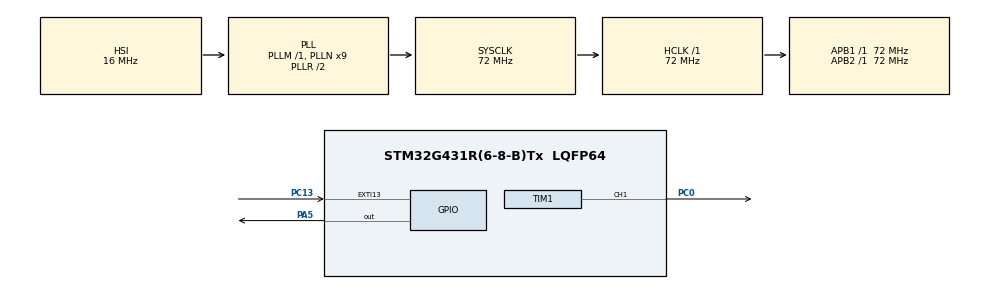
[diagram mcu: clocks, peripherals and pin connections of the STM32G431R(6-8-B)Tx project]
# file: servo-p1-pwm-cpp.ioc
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Mcu.Family=STM32G4
Mcu.Name=STM32G431R(6-8-B)Tx
Mcu.Package=LQFP64
NUCLEO-G431RB.BUTTON=1
NUCLEO-G431RB.LD1=true
NUCLEO-G431RB.VCP=true
NVIC.EXTI15_10_IRQn=true\:0\:0\:false\:false\:true\:false\:true\:true
NVIC.PriorityGroup=NVIC_PRIORITYGROUP_4
PA13.GPIO_Label=T_SWDIO
PA13.Signal=SYS_JTMS-SWDIO
PA14.GPIO_Label=T_SWCLK
PA14.Signal=SYS_JTCK-SWCLK
PA2.Signal=LPUART1_TX
PA3.Signal=LPUART1_RX
PA5.Signal=GPIO_Output
PB3.GPIO_Label=T_SWO
PB3.Signal=SYS_JTDO-SWO
PC0.Signal=S_TIM1_CH1
PC13.Signal=GPXTI13
PC14-OSC32_IN.GPIO_Label=RCC_OSC32_OUT
PC14-OSC32_IN.Signal=RCC_OSC32_IN
PC15-OSC32_OUT.GPIO_Label=RCC_OSC32_OUT
PC15-OSC32_OUT.Signal=RCC_OSC32_OUT
PF0-OSC_IN.GPIO_Label=RCC_OSC_IN
PF0-OSC_IN.Signal=RCC_OSC_IN
PF1-OSC_OUT.GPIO_Label=RCC_OSC_OUT
PF1-OSC_OUT.Signal=RCC_OSC_OUT
ProjectManager.HeapSize=0x200
ProjectManager.StackSize=0x400
ProjectManager.TargetToolchain=STM32CubeIDE
RCC.ADC12Freq_Value=72000000
RCC.AHBFreq_Value=72000000
RCC.APB1Freq_Value=72000000
RCC.APB1TimFreq_Value=72000000
RCC.APB2Freq_Value=72000000
RCC.APB2TimFreq_Value=72000000
RCC.CortexFreq_Value=72000000
RCC.EXTERNAL_CLOCK_VALUE=12288000
RCC.HCLKFreq_Value=72000000
RCC.HSE_VALUE=24000000
RCC.HSI48_VALUE=48000000
RCC.HSI_VALUE=16000000
RCC.LSE_VALUE=32768
RCC.PLLN=9
RCC.RTCClockSelection=RCC_RTCCLKSOURCE_LSE
RCC.SYSCLKFreq_VALUE=72000000
RCC.SYSCLKSource=RCC_SYSCLKSOURCE_PLLCLK
RCC.USBFreq_Value=72000000
RCC.VCOOutputFreq_Value=144000000
SH.S_TIM1_CH1.0=TIM1_CH1,PWM Generation1 CH1
TIM1.Channel-PWM\ Generation1\ CH1=TIM_CHANNEL_1
TIM1.PeriodNoDither=19999
TIM1.Prescaler=71
VP_NUCLEO-G431RB_VS_BSP_COMMON.Mode=COMMON
VP_SYS_VS_DBSignals.Mode=DisableDeadBatterySignals
board=NUCLEO-G431RB

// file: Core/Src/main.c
/* USER CODE BEGIN Header */
/**
  ******************************************************************************
  * @file           : main.c
  * @brief          : Main program body
  ******************************************************************************
  * @attention
  *
  * Copyright (c) 2024 STMicroelectronics.
  * All rights reserved.
  *
  * This software is licensed under terms that can be found in the LICENSE file
  * in the root directory of this software component.
  * If no LICENSE file comes with this software, it is provided AS-IS.
  *
  ******************************************************************************
  */
/* USER CODE END Header */
#include "main.h"

/* USER CODE BEGIN Includes */
#include "new_main.h"

/* USER CODE END Includes */

COM_InitTypeDef BspCOMInit;
TIM_HandleTypeDef htim1;

void SystemClock_Config(void);
static void MX_GPIO_Init(void);
static void MX_TIM1_Init(void);

int main(void)
{

  /* MCU Configuration--------------------------------------------------------*/

  /* Reset of all peripherals, Initializes the Flash interface and the Systick. */
  HAL_Init();

  /* Configure the system clock */
  SystemClock_Config();

  /* Initialize all configured peripherals */
  MX_GPIO_Init();
  MX_TIM1_Init();

  /* Initialize leds */
  BSP_LED_Init(LED_GREEN);

  /* Initialize USER push-button, will be used to trigger an interrupt each time it's pressed.*/
  BSP_PB_Init(BUTTON_USER, BUTTON_MODE_EXTI);

  /* Initialize COM1 port (115200, 8 bits (7-bit data + 1 stop bit), no parity */
  BspCOMInit.BaudRate   = 115200;
  BspCOMInit.WordLength = COM_WORDLENGTH_8B;
  BspCOMInit.StopBits   = COM_STOPBITS_1;
  BspCOMInit.Parity     = COM_PARITY_NONE;
  BspCOMInit.HwFlowCtl  = COM_HWCONTROL_NONE;
  if (BSP_COM_Init(COM1, &BspCOMInit) != BSP_ERROR_NONE)
  {
    Error_Handler();
  }

  /* Infinite loop */
  /* USER CODE BEGIN WHILE */
  new_main();
  while (1)
  {

    /* USER CODE END WHILE */

  }
}

void SystemClock_Config(void)
{
  RCC_OscInitTypeDef RCC_OscInitStruct = {0};
  RCC_ClkInitTypeDef RCC_ClkInitStruct = {0};

  /** Configure the main internal regulator output voltage
  */
  HAL_PWREx_ControlVoltageScaling(PWR_REGULATOR_VOLTAGE_SCALE1);

  /** Initializes the RCC Oscillators according to the specified parameters
  * in the RCC_OscInitTypeDef structure.
  */
  RCC_OscInitStruct.OscillatorType = RCC_OSCILLATORTYPE_HSI;
  RCC_OscInitStruct.HSIState = RCC_HSI_ON;
  RCC_OscInitStruct.HSICalibrationValue = RCC_HSICALIBRATION_DEFAULT;
  RCC_OscInitStruct.PLL.PLLState = RCC_PLL_ON;
  RCC_OscInitStruct.PLL.PLLSource = RCC_PLLSOURCE_HSI;
  RCC_OscInitStruct.PLL.PLLM = RCC_PLLM_DIV1;
  RCC_OscInitStruct.PLL.PLLN = 9;
  RCC_OscInitStruct.PLL.PLLP = RCC_PLLP_DIV2;
  RCC_OscInitStruct.PLL.PLLQ = RCC_PLLQ_DIV2;
  RCC_OscInitStruct.PLL.PLLR = RCC_PLLR_DIV2;
  if (HAL_RCC_OscConfig(&RCC_OscInitStruct) != HAL_OK)
  {
    Error_Handler();
  }

  /** Initializes the CPU, AHB and APB buses clocks
  */
  RCC_ClkInitStruct.ClockType = RCC_CLOCKTYPE_HCLK|RCC_CLOCKTYPE_SYSCLK
                              |RCC_CLOCKTYPE_PCLK1|RCC_CLOCKTYPE_PCLK2;
  RCC_ClkInitStruct.SYSCLKSource = RCC_SYSCLKSOURCE_PLLCLK;
  RCC_ClkInitStruct.AHBCLKDivider = RCC_SYSCLK_DIV1;
  RCC_ClkInitStruct.APB1CLKDivider = RCC_HCLK_DIV1;
  RCC_ClkInitStruct.APB2CLKDivider = RCC_HCLK_DIV1;

  if (HAL_RCC_ClockConfig(&RCC_ClkInitStruct, FLASH_LATENCY_2) != HAL_OK)
  {
    Error_Handler();
  }
}

static void MX_TIM1_Init(void)
{

  TIM_MasterConfigTypeDef sMasterConfig = {0};
  TIM_OC_InitTypeDef sConfigOC = {0};
  TIM_BreakDeadTimeConfigTypeDef sBreakDeadTimeConfig = {0};

  htim1.Instance = TIM1;
  htim1.Init.Prescaler = 71;
  htim1.Init.CounterMode = TIM_COUNTERMODE_UP;
  htim1.Init.Period = 19999;
  htim1.Init.ClockDivision = TIM_CLOCKDIVISION_DIV1;
  htim1.Init.RepetitionCounter = 0;
  htim1.Init.AutoReloadPreload = TIM_AUTORELOAD_PRELOAD_DISABLE;
  if (HAL_TIM_PWM_Init(&htim1) != HAL_OK)
  {
    Error_Handler();
  }
  sMasterConfig.MasterOutputTrigger = TIM_TRGO_RESET;
  sMasterConfig.MasterOutputTrigger2 = TIM_TRGO2_RESET;
  sMasterConfig.MasterSlaveMode = TIM_MASTERSLAVEMODE_DISABLE;
  if (HAL_TIMEx_MasterConfigSynchronization(&htim1, &sMasterConfig) != HAL_OK)
  {
    Error_Handler();
  }
  sConfigOC.OCMode = TIM_OCMODE_PWM1;
  sConfigOC.Pulse = 0;
  sConfigOC.OCPolarity = TIM_OCPOLARITY_HIGH;
  sConfigOC.OCNPolarity = TIM_OCNPOLARITY_HIGH;
  sConfigOC.OCFastMode = TIM_OCFAST_DISABLE;
  sConfigOC.OCIdleState = TIM_OCIDLESTATE_RESET;
  sConfigOC.OCNIdleState = TIM_OCNIDLESTATE_RESET;
  if (HAL_TIM_PWM_ConfigChannel(&htim1, &sConfigOC, TIM_CHANNEL_1) != HAL_OK)
  {
    Error_Handler();
  }
  sBreakDeadTimeConfig.OffStateRunMode = TIM_OSSR_DISABLE;
  sBreakDeadTimeConfig.OffStateIDLEMode = TIM_OSSI_DISABLE;
  sBreakDeadTimeConfig.LockLevel = TIM_LOCKLEVEL_OFF;
  sBreakDeadTimeConfig.DeadTime = 0;
  sBreakDeadTimeConfig.BreakState = TIM_BREAK_DISABLE;
  sBreakDeadTimeConfig.BreakPolarity = TIM_BREAKPOLARITY_HIGH;
  sBreakDeadTimeConfig.BreakFilter = 0;
  sBreakDeadTimeConfig.BreakAFMode = TIM_BREAK_AFMODE_INPUT;
  sBreakDeadTimeConfig.Break2State = TIM_BREAK2_DISABLE;
  sBreakDeadTimeConfig.Break2Polarity = TIM_BREAK2POLARITY_HIGH;
  sBreakDeadTimeConfig.Break2Filter = 0;
  sBreakDeadTimeConfig.Break2AFMode = TIM_BREAK_AFMODE_INPUT;
  sBreakDeadTimeConfig.AutomaticOutput = TIM_AUTOMATICOUTPUT_DISABLE;
  if (HAL_TIMEx_ConfigBreakDeadTime(&htim1, &sBreakDeadTimeConfig) != HAL_OK)
  {
    Error_Handler();
  }
  HAL_TIM_MspPostInit(&htim1);

}

static void MX_GPIO_Init(void)
{

  /* GPIO Ports Clock Enable */
  __HAL_RCC_GPIOC_CLK_ENABLE();
  __HAL_RCC_GPIOF_CLK_ENABLE();
  __HAL_RCC_GPIOA_CLK_ENABLE();
  __HAL_RCC_GPIOB_CLK_ENABLE();

}

void Error_Handler(void)
{
  __disable_irq();
  while (1)
  {
  }
}
